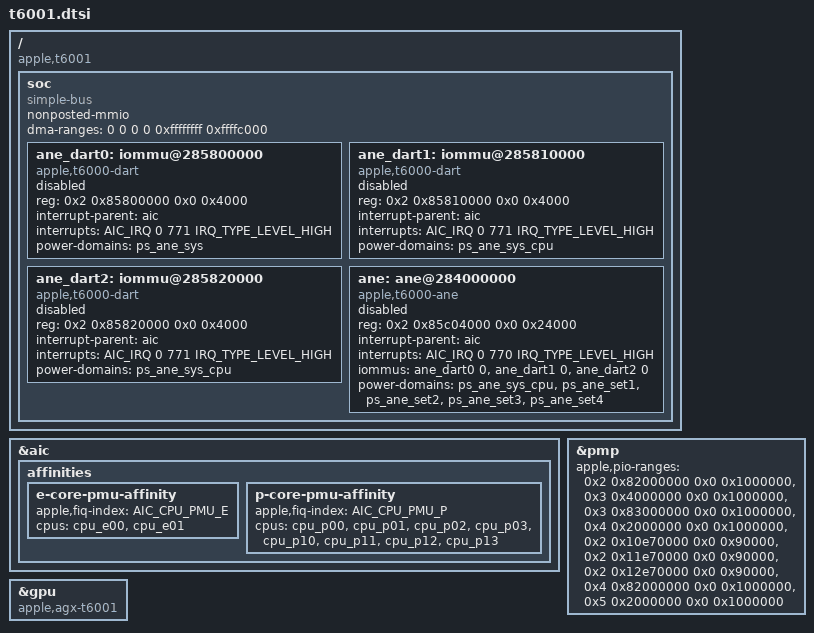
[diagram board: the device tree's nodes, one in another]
// SPDX-License-Identifier: GPL-2.0+ OR MIT
/*
 * Apple T6001 "M1 Max" SoC
 *
 * Other names: H13J, "Jade"
 *
 * Copyright The Asahi Linux Contributors
 */

#include <dt-bindings/gpio/gpio.h>
#include <dt-bindings/interrupt-controller/apple-aic.h>
#include <dt-bindings/interrupt-controller/irq.h>
#include <dt-bindings/pinctrl/apple.h>
#include <dt-bindings/phy/phy.h>
#include <dt-bindings/spmi/spmi.h>

#include "multi-die-cpp.h"

#ifndef GPU_REPEAT
# define GPU_REPEAT(x) <x x x x>
#endif

#include "t600x-common.dtsi"

/ {
	compatible = "apple,t6001", "apple,arm-platform";

	soc {
		compatible = "simple-bus";
		#address-cells = <2>;
		#size-cells = <2>;

		ranges;
		nonposted-mmio;
		/* Required to get >32-bit DMA via DARTs */
		dma-ranges = <0 0 0 0 0xffffffff 0xffffc000>;

		// filled via templated includes at the end of the file
	};
};

#define DIE
#define DIE_NO 0

&{/soc} {
	#include "t600x-die0.dtsi"
	#include "t600x-dieX.dtsi"
	#include "t600x-nvme.dtsi"
};

#include "t600x-gpio-pins.dtsi"
#include "t600x-pmgr.dtsi"

#undef DIE
#undef DIE_NO


&aic {
	affinities {
		e-core-pmu-affinity {
			apple,fiq-index = <AIC_CPU_PMU_E>;
			cpus = <&cpu_e00 &cpu_e01>;
		};

		p-core-pmu-affinity {
			apple,fiq-index = <AIC_CPU_PMU_P>;
			cpus = <&cpu_p00 &cpu_p01 &cpu_p02 &cpu_p03
				&cpu_p10 &cpu_p11 &cpu_p12 &cpu_p13>;
		};
	};
};

&pmp {
	apple,pio-ranges = <0x2 0x82000000 0x0 0x1000000>,
		<0x3 0x4000000 0x0 0x1000000>,
		<0x3 0x83000000 0x0 0x1000000>,
		<0x4 0x2000000 0x0 0x1000000>,
		<0x2 0x10e70000 0x0 0x90000>,
		<0x2 0x11e70000 0x0 0x90000>,
		<0x2 0x12e70000 0x0 0x90000>,
		<0x4 0x82000000 0x0 0x1000000>,
		<0x5 0x2000000 0x0 0x1000000>;
};

&gpu {
	compatible = "apple,agx-t6001", "apple,agx-g13c", "apple,agx-g13s";
};

&{/soc} {
	ane_dart0: iommu@285800000 {
		compatible = "apple,t6000-dart";
		reg = <0x2 0x85800000 0x0 0x4000>;
		#iommu-cells = <1>;
		interrupt-parent = <&aic>;
		interrupts = <AIC_IRQ 0 771 IRQ_TYPE_LEVEL_HIGH>;
		power-domains = <&ps_ane_sys>;
		status = "disabled";
	};

	ane_dart1: iommu@285810000 {
		compatible = "apple,t6000-dart";
		reg = <0x2 0x85810000 0x0 0x4000>;
		#iommu-cells = <1>;
		interrupt-parent = <&aic>;
		interrupts = <AIC_IRQ 0 771 IRQ_TYPE_LEVEL_HIGH>;
		power-domains = <&ps_ane_sys_cpu>;
		status = "disabled";
	};

	ane_dart2: iommu@285820000 {
		compatible = "apple,t6000-dart";
		reg = <0x2 0x85820000 0x0 0x4000>;
		#iommu-cells = <1>;
		interrupt-parent = <&aic>;
		interrupts = <AIC_IRQ 0 771 IRQ_TYPE_LEVEL_HIGH>;
		power-domains = <&ps_ane_sys_cpu>;
		status = "disabled";
	};

	ane: ane@284000000 {
		compatible = "apple,t6000-ane";
		reg-names = "engine";
		reg = <0x2 0x85c04000 0x0 0x24000>;
		interrupt-parent = <&aic>;
		interrupt-names = "ane";
		interrupts = <AIC_IRQ 0 770 IRQ_TYPE_LEVEL_HIGH>;
		iommus = <&ane_dart0 0>, <&ane_dart1 0>, <&ane_dart2 0>;
		power-domains = <&ps_ane_sys_cpu>, <&ps_ane_set1>,
			<&ps_ane_set2>, <&ps_ane_set3>, <&ps_ane_set4>;
		status = "disabled";
	};
};
